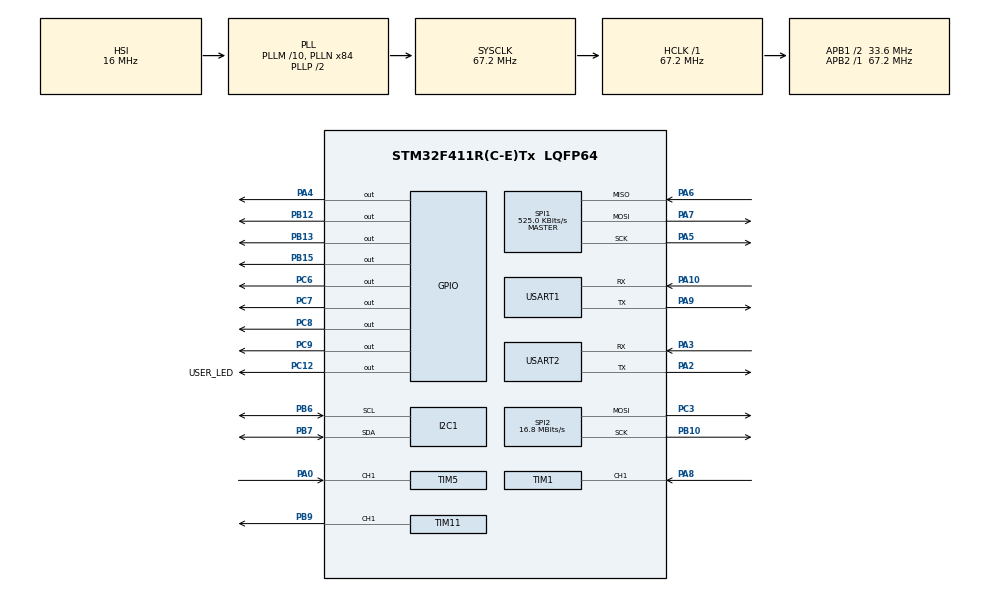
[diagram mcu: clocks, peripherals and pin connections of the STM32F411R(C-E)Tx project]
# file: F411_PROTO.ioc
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Mcu.Family=STM32F4
Mcu.Name=STM32F411R(C-E)Tx
Mcu.Package=LQFP64
NVIC.PriorityGroup=NVIC_PRIORITYGROUP_4
PA0-WKUP.Signal=S_TIM5_CH1
PA10.Mode=Asynchronous
PA10.Signal=USART1_RX
PA13.Mode=Serial_Wire
PA13.Signal=SYS_JTMS-SWDIO
PA14.Mode=Serial_Wire
PA14.Signal=SYS_JTCK-SWCLK
PA2.Mode=Asynchronous
PA2.Signal=USART2_TX
PA3.Mode=Asynchronous
PA3.Signal=USART2_RX
PA4.Signal=GPIO_Output
PA5.Mode=Full_Duplex_Master
PA5.Signal=SPI1_SCK
PA6.Mode=Full_Duplex_Master
PA6.Signal=SPI1_MISO
PA7.Mode=Full_Duplex_Master
PA7.Signal=SPI1_MOSI
PA8.Signal=S_TIM1_CH1
PA9.Mode=Asynchronous
PA9.Signal=USART1_TX
PB10.Mode=TX_Only_Simplex_Unidirect_Master
PB10.Signal=SPI2_SCK
PB12.Signal=GPIO_Output
PB13.Signal=GPIO_Output
PB15.Signal=GPIO_Output
PB6.Mode=I2C
PB6.Signal=I2C1_SCL
PB7.Mode=I2C
PB7.Signal=I2C1_SDA
PB9.Signal=S_TIM11_CH1
PC12.GPIO_Label=USER_LED
PC12.Signal=GPIO_Output
PC3.Mode=TX_Only_Simplex_Unidirect_Master
PC3.Signal=SPI2_MOSI
PC6.Signal=GPIO_Output
PC7.Signal=GPIO_Output
PC8.Signal=GPIO_Output
PC9.Signal=GPIO_Output
PH0\ -\ OSC_IN.Mode=HSE-External-Oscillator
PH0\ -\ OSC_IN.Signal=RCC_OSC_IN
PH1\ -\ OSC_OUT.Mode=HSE-External-Oscillator
PH1\ -\ OSC_OUT.Signal=RCC_OSC_OUT
ProjectManager.HeapSize=0x200
ProjectManager.StackSize=0x400
ProjectManager.TargetToolchain=SW4STM32
RCC.48MHZClocksFreq_Value=33600000
RCC.AHBFreq_Value=67200000
RCC.APB1CLKDivider=RCC_HCLK_DIV2
RCC.APB1Freq_Value=33600000
RCC.APB1TimFreq_Value=67200000
RCC.APB2Freq_Value=67200000
RCC.APB2TimFreq_Value=67200000
RCC.CortexFreq_Value=67200000
RCC.HCLKFreq_Value=67200000
RCC.HSE_VALUE=20000000
RCC.HSI_VALUE=16000000
RCC.LSE_VALUE=32768
RCC.PLLM=10
RCC.PLLN=84
RCC.SYSCLKFreq_VALUE=67200000
RCC.SYSCLKSource=RCC_SYSCLKSOURCE_PLLCLK
RCC.VCOOutputFreq_Value=134400000
SH.S_TIM11_CH1.0=TIM11_CH1,PWM Generation1 CH1
SH.S_TIM1_CH1.0=TIM1_CH1,Input_Capture1_from_TI1
SH.S_TIM5_CH1.0=TIM5_CH1,Input_Capture1_from_TI1
SPI1.BaudRatePrescaler=SPI_BAUDRATEPRESCALER_128
SPI1.CalculateBaudRate=525.0 KBits/s
SPI1.Mode=SPI_MODE_MASTER
SPI2.BaudRatePrescaler=SPI_BAUDRATEPRESCALER_2
SPI2.CalculateBaudRate=16.8 MBits/s
SPI2.Mode=SPI_MODE_MASTER
VP_TIM11_VS_ClockSourceINT.Mode=Enable_Timer
board=F411_PROTO

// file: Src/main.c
/**
  ******************************************************************************
  * File Name          : main.c
  * Description        : Main program body
  ******************************************************************************
  *
  * COPYRIGHT(c) 2016 STMicroelectronics
  *
  * Redistribution and use in source and binary forms, with or without modification,
  * are permitted provided that the following conditions are met:
  *   1. Redistributions of source code must retain the above copyright notice,
  *      this list of conditions and the following disclaimer.
  *   2. Redistributions in binary form must reproduce the above copyright notice,
  *      this list of conditions and the following disclaimer in the documentation
  *      and/or other materials provided with the distribution.
  *   3. Neither the name of STMicroelectronics nor the names of its contributors
  *      may be used to endorse or promote products derived from this software
  *      without specific prior written permission.
  *
  * THIS SOFTWARE IS PROVIDED BY THE COPYRIGHT HOLDERS AND CONTRIBUTORS "AS IS"
  * AND ANY EXPRESS OR IMPLIED WARRANTIES, INCLUDING, BUT NOT LIMITED TO, THE
  * IMPLIED WARRANTIES OF MERCHANTABILITY AND FITNESS FOR A PARTICULAR PURPOSE ARE
  * DISCLAIMED. IN NO EVENT SHALL THE COPYRIGHT HOLDER OR CONTRIBUTORS BE LIABLE
  * FOR ANY DIRECT, INDIRECT, INCIDENTAL, SPECIAL, EXEMPLARY, OR CONSEQUENTIAL
  * DAMAGES (INCLUDING, BUT NOT LIMITED TO, PROCUREMENT OF SUBSTITUTE GOODS OR
  * SERVICES; LOSS OF USE, DATA, OR PROFITS; OR BUSINESS INTERRUPTION) HOWEVER
  * CAUSED AND ON ANY THEORY OF LIABILITY, WHETHER IN CONTRACT, STRICT LIABILITY,
  * OR TORT (INCLUDING NEGLIGENCE OR OTHERWISE) ARISING IN ANY WAY OUT OF THE USE
  * OF THIS SOFTWARE, EVEN IF ADVISED OF THE POSSIBILITY OF SUCH DAMAGE.
  *
  ******************************************************************************
  */
#include "stm32f4xx_hal.h"

I2C_HandleTypeDef hi2c1;

SPI_HandleTypeDef hspi1;
SPI_HandleTypeDef hspi2;

TIM_HandleTypeDef htim1;
TIM_HandleTypeDef htim5;
TIM_HandleTypeDef htim11;

UART_HandleTypeDef huart1;
UART_HandleTypeDef huart2;

/* USER CODE BEGIN PV */
/* Private variables ---------------------------------------------------------*/

/* USER CODE END PV */

void SystemClock_Config(void);
void Error_Handler(void);
static void MX_GPIO_Init(void);
static void MX_I2C1_Init(void);
static void MX_SPI1_Init(void);
static void MX_SPI2_Init(void);
static void MX_TIM1_Init(void);
static void MX_TIM5_Init(void);
static void MX_TIM11_Init(void);
static void MX_USART1_UART_Init(void);
static void MX_USART2_UART_Init(void);

void HAL_TIM_MspPostInit(TIM_HandleTypeDef *htim);

/* USER CODE BEGIN PFP */
/* Private function prototypes -----------------------------------------------*/

/* USER CODE END PFP */

int main(void)
{

  /* USER CODE BEGIN 1 */
	uint8_t temp = 0x11;
  /* USER CODE END 1 */

  /* MCU Configuration----------------------------------------------------------*/

  /* Reset of all peripherals, Initializes the Flash interface and the Systick. */
  HAL_Init();

  /* Configure the system clock */
  SystemClock_Config();

  /* Initialize all configured peripherals */
  MX_GPIO_Init();
  MX_I2C1_Init();
  MX_SPI1_Init();
  MX_SPI2_Init();
  MX_TIM1_Init();
  MX_TIM5_Init();
  MX_TIM11_Init();
  MX_USART1_UART_Init();
  MX_USART2_UART_Init();

  /* Infinite loop */
  while (1)
  {

  /* USER CODE BEGIN 3 */
	  HAL_I2C_Mem_Write(&hi2c1, 0x90, 0x00, 1, &temp, 1, 5000);
	  HAL_UART_Transmit(&huart1,&temp,1,5000);
	  HAL_SPI_Transmit(&hspi1,&temp,1,5000);
  }
  /* USER CODE END 3 */

}

/** System Clock Configuration
*/
void SystemClock_Config(void)
{

  RCC_OscInitTypeDef RCC_OscInitStruct;
  RCC_ClkInitTypeDef RCC_ClkInitStruct;

  __HAL_RCC_PWR_CLK_ENABLE();

  __HAL_PWR_VOLTAGESCALING_CONFIG(PWR_REGULATOR_VOLTAGE_SCALE1);

  RCC_OscInitStruct.OscillatorType = RCC_OSCILLATORTYPE_HSI;
  RCC_OscInitStruct.HSIState = RCC_HSI_ON;
  RCC_OscInitStruct.HSICalibrationValue = 16;
  RCC_OscInitStruct.PLL.PLLState = RCC_PLL_ON;
  RCC_OscInitStruct.PLL.PLLSource = RCC_PLLSOURCE_HSI;
  RCC_OscInitStruct.PLL.PLLM = 10;
  RCC_OscInitStruct.PLL.PLLN = 84;
  RCC_OscInitStruct.PLL.PLLP = RCC_PLLP_DIV2;
  RCC_OscInitStruct.PLL.PLLQ = 4;
  if (HAL_RCC_OscConfig(&RCC_OscInitStruct) != HAL_OK)
  {
    Error_Handler();
  }

  RCC_ClkInitStruct.ClockType = RCC_CLOCKTYPE_HCLK|RCC_CLOCKTYPE_SYSCLK
                              |RCC_CLOCKTYPE_PCLK1|RCC_CLOCKTYPE_PCLK2;
  RCC_ClkInitStruct.SYSCLKSource = RCC_SYSCLKSOURCE_PLLCLK;
  RCC_ClkInitStruct.AHBCLKDivider = RCC_SYSCLK_DIV1;
  RCC_ClkInitStruct.APB1CLKDivider = RCC_HCLK_DIV2;
  RCC_ClkInitStruct.APB2CLKDivider = RCC_HCLK_DIV1;
  if (HAL_RCC_ClockConfig(&RCC_ClkInitStruct, FLASH_LATENCY_2) != HAL_OK)
  {
    Error_Handler();
  }

  HAL_SYSTICK_Config(HAL_RCC_GetHCLKFreq()/1000);

  HAL_SYSTICK_CLKSourceConfig(SYSTICK_CLKSOURCE_HCLK);

  /* SysTick_IRQn interrupt configuration */
  HAL_NVIC_SetPriority(SysTick_IRQn, 0, 0);
}

/* I2C1 init function */
static void MX_I2C1_Init(void)
{

  hi2c1.Instance = I2C1;
  hi2c1.Init.ClockSpeed = 100000;
  hi2c1.Init.DutyCycle = I2C_DUTYCYCLE_2;
  hi2c1.Init.OwnAddress1 = 0;
  hi2c1.Init.AddressingMode = I2C_ADDRESSINGMODE_7BIT;
  hi2c1.Init.DualAddressMode = I2C_DUALADDRESS_DISABLE;
  hi2c1.Init.OwnAddress2 = 0;
  hi2c1.Init.GeneralCallMode = I2C_GENERALCALL_DISABLE;
  hi2c1.Init.NoStretchMode = I2C_NOSTRETCH_DISABLE;
  if (HAL_I2C_Init(&hi2c1) != HAL_OK)
  {
    Error_Handler();
  }

}

/* SPI1 init function */
static void MX_SPI1_Init(void)
{

  hspi1.Instance = SPI1;
  hspi1.Init.Mode = SPI_MODE_MASTER;
  hspi1.Init.Direction = SPI_DIRECTION_2LINES;
  hspi1.Init.DataSize = SPI_DATASIZE_8BIT;
  hspi1.Init.CLKPolarity = SPI_POLARITY_LOW;
  hspi1.Init.CLKPhase = SPI_PHASE_1EDGE;
  hspi1.Init.NSS = SPI_NSS_SOFT;
  hspi1.Init.BaudRatePrescaler = SPI_BAUDRATEPRESCALER_128;
  hspi1.Init.FirstBit = SPI_FIRSTBIT_MSB;
  hspi1.Init.TIMode = SPI_TIMODE_DISABLE;
  hspi1.Init.CRCCalculation = SPI_CRCCALCULATION_DISABLE;
  hspi1.Init.CRCPolynomial = 10;
  if (HAL_SPI_Init(&hspi1) != HAL_OK)
  {
    Error_Handler();
  }

}

/* SPI2 init function */
static void MX_SPI2_Init(void)
{

  hspi2.Instance = SPI2;
  hspi2.Init.Mode = SPI_MODE_MASTER;
  hspi2.Init.Direction = SPI_DIRECTION_2LINES;
  hspi2.Init.DataSize = SPI_DATASIZE_8BIT;
  hspi2.Init.CLKPolarity = SPI_POLARITY_LOW;
  hspi2.Init.CLKPhase = SPI_PHASE_1EDGE;
  hspi2.Init.NSS = SPI_NSS_SOFT;
  hspi2.Init.BaudRatePrescaler = SPI_BAUDRATEPRESCALER_2;
  hspi2.Init.FirstBit = SPI_FIRSTBIT_MSB;
  hspi2.Init.TIMode = SPI_TIMODE_DISABLE;
  hspi2.Init.CRCCalculation = SPI_CRCCALCULATION_DISABLE;
  hspi2.Init.CRCPolynomial = 10;
  if (HAL_SPI_Init(&hspi2) != HAL_OK)
  {
    Error_Handler();
  }

}

/* TIM1 init function */
static void MX_TIM1_Init(void)
{

  TIM_MasterConfigTypeDef sMasterConfig;
  TIM_IC_InitTypeDef sConfigIC;

  htim1.Instance = TIM1;
  htim1.Init.Prescaler = 0;
  htim1.Init.CounterMode = TIM_COUNTERMODE_UP;
  htim1.Init.Period = 0;
  htim1.Init.ClockDivision = TIM_CLOCKDIVISION_DIV1;
  htim1.Init.RepetitionCounter = 0;
  if (HAL_TIM_IC_Init(&htim1) != HAL_OK)
  {
    Error_Handler();
  }

  sMasterConfig.MasterOutputTrigger = TIM_TRGO_RESET;
  sMasterConfig.MasterSlaveMode = TIM_MASTERSLAVEMODE_DISABLE;
  if (HAL_TIMEx_MasterConfigSynchronization(&htim1, &sMasterConfig) != HAL_OK)
  {
    Error_Handler();
  }

  sConfigIC.ICPolarity = TIM_INPUTCHANNELPOLARITY_RISING;
  sConfigIC.ICSelection = TIM_ICSELECTION_DIRECTTI;
  sConfigIC.ICPrescaler = TIM_ICPSC_DIV1;
  sConfigIC.ICFilter = 0;
  if (HAL_TIM_IC_ConfigChannel(&htim1, &sConfigIC, TIM_CHANNEL_1) != HAL_OK)
  {
    Error_Handler();
  }

}

/* TIM5 init function */
static void MX_TIM5_Init(void)
{

  TIM_MasterConfigTypeDef sMasterConfig;
  TIM_IC_InitTypeDef sConfigIC;

  htim5.Instance = TIM5;
  htim5.Init.Prescaler = 0;
  htim5.Init.CounterMode = TIM_COUNTERMODE_UP;
  htim5.Init.Period = 0;
  htim5.Init.ClockDivision = TIM_CLOCKDIVISION_DIV1;
  if (HAL_TIM_IC_Init(&htim5) != HAL_OK)
  {
    Error_Handler();
  }

  sMasterConfig.MasterOutputTrigger = TIM_TRGO_RESET;
  sMasterConfig.MasterSlaveMode = TIM_MASTERSLAVEMODE_DISABLE;
  if (HAL_TIMEx_MasterConfigSynchronization(&htim5, &sMasterConfig) != HAL_OK)
  {
    Error_Handler();
  }

  sConfigIC.ICPolarity = TIM_INPUTCHANNELPOLARITY_RISING;
  sConfigIC.ICSelection = TIM_ICSELECTION_DIRECTTI;
  sConfigIC.ICPrescaler = TIM_ICPSC_DIV1;
  sConfigIC.ICFilter = 0;
  if (HAL_TIM_IC_ConfigChannel(&htim5, &sConfigIC, TIM_CHANNEL_1) != HAL_OK)
  {
    Error_Handler();
  }

}

/* TIM11 init function */
static void MX_TIM11_Init(void)
{

  TIM_OC_InitTypeDef sConfigOC;

  htim11.Instance = TIM11;
  htim11.Init.Prescaler = 0;
  htim11.Init.CounterMode = TIM_COUNTERMODE_UP;
  htim11.Init.Period = 0;
  htim11.Init.ClockDivision = TIM_CLOCKDIVISION_DIV1;
  if (HAL_TIM_Base_Init(&htim11) != HAL_OK)
  {
    Error_Handler();
  }

  if (HAL_TIM_PWM_Init(&htim11) != HAL_OK)
  {
    Error_Handler();
  }

  sConfigOC.OCMode = TIM_OCMODE_PWM1;
  sConfigOC.Pulse = 0;
  sConfigOC.OCPolarity = TIM_OCPOLARITY_HIGH;
  sConfigOC.OCFastMode = TIM_OCFAST_DISABLE;
  if (HAL_TIM_PWM_ConfigChannel(&htim11, &sConfigOC, TIM_CHANNEL_1) != HAL_OK)
  {
    Error_Handler();
  }

  HAL_TIM_MspPostInit(&htim11);

}

/* USART1 init function */
static void MX_USART1_UART_Init(void)
{

  huart1.Instance = USART1;
  huart1.Init.BaudRate = 115200;
  huart1.Init.WordLength = UART_WORDLENGTH_8B;
  huart1.Init.StopBits = UART_STOPBITS_1;
  huart1.Init.Parity = UART_PARITY_NONE;
  huart1.Init.Mode = UART_MODE_TX_RX;
  huart1.Init.HwFlowCtl = UART_HWCONTROL_NONE;
  huart1.Init.OverSampling = UART_OVERSAMPLING_16;
  if (HAL_UART_Init(&huart1) != HAL_OK)
  {
    Error_Handler();
  }

}

/* USART2 init function */
static void MX_USART2_UART_Init(void)
{

  huart2.Instance = USART2;
  huart2.Init.BaudRate = 115200;
  huart2.Init.WordLength = UART_WORDLENGTH_8B;
  huart2.Init.StopBits = UART_STOPBITS_1;
  huart2.Init.Parity = UART_PARITY_NONE;
  huart2.Init.Mode = UART_MODE_TX_RX;
  huart2.Init.HwFlowCtl = UART_HWCONTROL_NONE;
  huart2.Init.OverSampling = UART_OVERSAMPLING_16;
  if (HAL_UART_Init(&huart2) != HAL_OK)
  {
    Error_Handler();
  }

}

/** Configure pins as
        * Analog
        * Input
        * Output
        * EVENT_OUT
        * EXTI
*/
static void MX_GPIO_Init(void)
{

  GPIO_InitTypeDef GPIO_InitStruct;

  /* GPIO Ports Clock Enable */
  __HAL_RCC_GPIOH_CLK_ENABLE();
  __HAL_RCC_GPIOC_CLK_ENABLE();
  __HAL_RCC_GPIOA_CLK_ENABLE();
  __HAL_RCC_GPIOB_CLK_ENABLE();

  /*Configure GPIO pin Output Level */
  HAL_GPIO_WritePin(GPIOA, GPIO_PIN_4, GPIO_PIN_RESET);

  /*Configure GPIO pin Output Level */
  HAL_GPIO_WritePin(GPIOB, GPIO_PIN_12|GPIO_PIN_13|GPIO_PIN_15, GPIO_PIN_RESET);

  /*Configure GPIO pin Output Level */
  HAL_GPIO_WritePin(GPIOC, GPIO_PIN_6|GPIO_PIN_7|GPIO_PIN_8|GPIO_PIN_9
                          |USER_LED_Pin, GPIO_PIN_RESET);

  /*Configure GPIO pin : PA4 */
  GPIO_InitStruct.Pin = GPIO_PIN_4;
  GPIO_InitStruct.Mode = GPIO_MODE_OUTPUT_PP;
  GPIO_InitStruct.Pull = GPIO_NOPULL;
  GPIO_InitStruct.Speed = GPIO_SPEED_FREQ_LOW;
  HAL_GPIO_Init(GPIOA, &GPIO_InitStruct);

  /*Configure GPIO pins : PB12 PB13 PB15 */
  GPIO_InitStruct.Pin = GPIO_PIN_12|GPIO_PIN_13|GPIO_PIN_15;
  GPIO_InitStruct.Mode = GPIO_MODE_OUTPUT_PP;
  GPIO_InitStruct.Pull = GPIO_NOPULL;
  GPIO_InitStruct.Speed = GPIO_SPEED_FREQ_LOW;
  HAL_GPIO_Init(GPIOB, &GPIO_InitStruct);

  /*Configure GPIO pins : PC6 PC7 PC8 PC9
                           USER_LED_Pin */
  GPIO_InitStruct.Pin = GPIO_PIN_6|GPIO_PIN_7|GPIO_PIN_8|GPIO_PIN_9
                          |USER_LED_Pin;
  GPIO_InitStruct.Mode = GPIO_MODE_OUTPUT_PP;
  GPIO_InitStruct.Pull = GPIO_NOPULL;
  GPIO_InitStruct.Speed = GPIO_SPEED_FREQ_LOW;
  HAL_GPIO_Init(GPIOC, &GPIO_InitStruct);

}

void Error_Handler(void)
{
  while(1)
  {
  }
}

/************************ (C) COPYRIGHT STMicroelectronics *****END OF FILE****/
